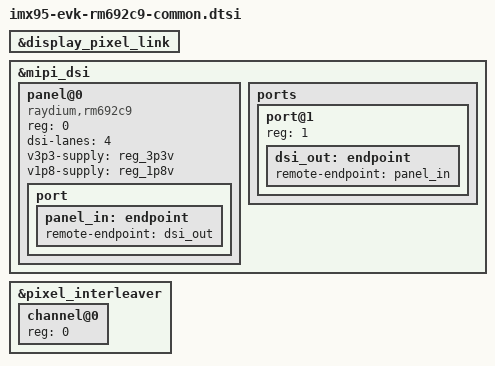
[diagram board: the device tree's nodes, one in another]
// SPDX-License-Identifier: (GPL-2.0+ OR MIT)
/*
 * Copyright 2026 NXP
 */

/dts-v1/;
/plugin/;

&display_pixel_link {
	status = "okay";
};

&mipi_dsi {
	#address-cells = <1>;
	#size-cells = <0>;
	status = "okay";

	panel@0 {
		compatible = "raydium,rm692c9";
		reg = <0>;
		dsi-lanes = <4>;
		v3p3-supply = <&reg_3p3v>;
		v1p8-supply = <&reg_1p8v>;

		port {
			panel_in: endpoint {
				remote-endpoint = <&dsi_out>;
			};
		};
	};

	ports {
		#address-cells = <1>;
		#size-cells = <0>;

		port@1 {
			reg = <1>;

			dsi_out: endpoint {
				remote-endpoint = <&panel_in>;
			};
		};
	};
};

&pixel_interleaver {
	#address-cells = <1>;
	#size-cells = <0>;
	status = "okay";

	channel@0 {
		reg = <0>;
		status = "okay";
	};
};
